# STM32H7RSxx register map
File version: 0.1
CPU: CM7 r0p1, little endian, MPU, FPU, 4 interrupt priority bits
Registers are 32-bit, read-write, reset 0x0 unless marked. A register's access mark holds for its fields unless they carry their own. Offsets are from the block's base; [hi:lo] are bit positions; lines under a group give offsets from that group; {n}, {i} and the like mark numbered series; <NAME> marks a mode.

## I3C1 (part 1 of 2) — Improved inter-integrated circuit
Base 0x40005400
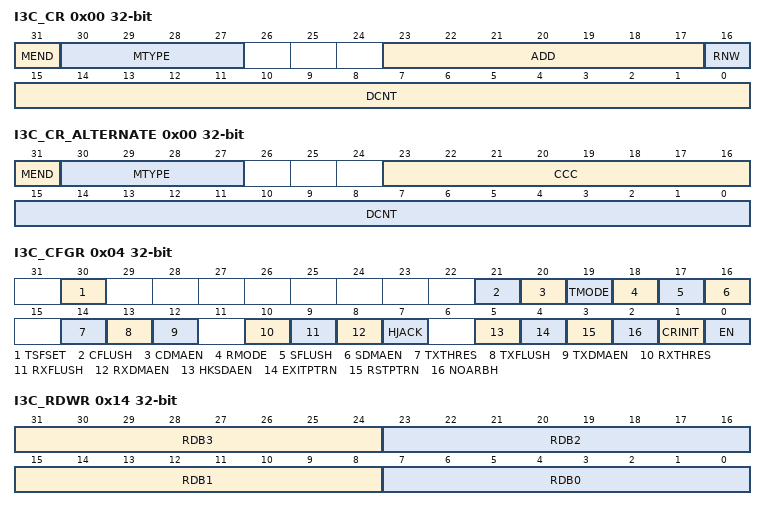
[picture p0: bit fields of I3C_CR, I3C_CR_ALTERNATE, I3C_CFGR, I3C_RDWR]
0x00 I3C_CR wo — I3C message control register
  [31] MEND — message end type (when the I3C is acting as controller)
    0=this message from controller ends with a Repeated START (Sr); 1=this message from controller ends with a STOP (P), being the last message of a frame
  [30:27] MTYPE — message type (whatever I3C is acting as controller/target) Bits[26:0] are ignored. After M2 error detection on an I3C SDR message, this is needed for SCL â€œstuck atâ€ recovery. Bits[26:0] are ignored. If I3C_CFGR.EXITPTRN=1, an HDR exit pattern is emitted on the bus to generate an escalation fault. Bits[23:17] (ADD[6:0]) is the emitted 7-bit dynamic address. Bit[16] (RNW) is the emitted RnW bit. The transferred private message is: {S / S+7â€™h7E+RnW=0+Sr / Sr+*} + 7-bit DynAddr + RnW + (8-bit Data + T)* + Sr/P. After a S (START), depending on I3C_CFGR.NOARBH, the arbitrable header (7â€™h7E+RnW=0) is inserted or not. Sr+*: after a Sr (Repeated Start), the hardware automatically inserts (7â€™h7E+RnW=0) if needed, i.e. if it follows an I3C direct message without ending by a P (Stop). Bits[23:17] (ADD[6:0]) is the emitted 7-bit dynamic address. Bit[16] (RNW) is the emitted RnW bit. The transferred direct message is: Sr + 7-bit DynAddr + RnW + (8-bit Data + T)* + Sr/P Bits[23:17] (ADD[6:0]) is the emitted 7-bit static address. Bit[16] (RNW) is the emitted RnW bit. The transferred legacy I2C message is: {S / S+ 7â€™h7E+RnW=0 + Sr / Sr+*} + 7-bit StaAddr + RnW + (8-bit Data + T)* + Sr/P. After a S (START), depending on I3C_CFGR.NOARBH, the arbitrable header (7â€™h7E+RnW=0) is inserted or not. Sr+*: after a Sr (Repeated Start), the hardware automatically inserts (7â€™h7E+RnW=0) if needed, i.e. if it follows an I3C direct message without ending by a P (Stop). 1xxx: reserved (when I3C is acting as I3C controller, used when target) 0xxx: reserved {S +} 7â€™h02 addr + RnW=0 {S +} 7-bit I3C_DEVR0.DA[6:0] + RnW=0 after a bus available condition (the target first emits a START request), or once the controller drives a START. {S +} 7-bit I3C_DEVR0.DA[6:0] + RnW=1 (+Ack/Nack from controller) When acknowledged from controller, the next (optional, depending on I3C_BCR.BCR2) transmitted IBI payload data is defined by I3C_CR.DCNT[15:0] and must be consistently programmed vs the maximum IBI payload data size which is defined by I3C_IBIDR.IBIP[2:0]. Others: reserved
    0=B_0x0_WHEN_I3C_IS_ACTING_AS_I3C_CONTROLLER (SCL output clock stops running until next control word is executed); 1=B_0x1_WHEN_I3C_IS_ACTING_AS_I3C_CONTROLLER (header message); 2=B_0x2_WHEN_I3C_IS_ACTING_AS_I3C_CONTROLLER (private message); 3=B_0x3_WHEN_I3C_IS_ACTING_AS_I3C_CONTROLLER (direct message (2nd part of an I3C SDR direct CCC command)); 4=B_0x4_WHEN_I3C_IS_ACTING_AS_I3C_CONTROLLER (legacy I2C message); 6=B_0x6_WHEN_I3C_IS_ACTING_AS_I3C_CONTROLLER (reserved (for this 1st alternate register description)); 8=B_0x8_WHEN_I3C_IS_ACTING_AS_I3C_TARGET (hot-join request (W)); 9=B_0x9_WHEN_I3C_IS_ACTING_AS_I3C_TARGET (controller-role request (W)); 10=B_0xA_WHEN_I3C_IS_ACTING_AS_I3C_TARGET (IBI (in-band interrupt) request (R))
  [23:17] ADD — 7-bit I3C dynamic / I2C static target address (when I3C is acting as controller) When I3C is acting as controller, this field is used if MTYPE[3:0]=0010 (private message) or MTYPE[3:0]=0011 (direct message) or MTYPE[3:0]=0100 (legacy I2C message)
  [16] RNW — read / non-write message (when I3C is acting as controller) When I3C is acting as controller, this field is used if MTYPE[3:0]=0010 (private message) or MTYPE[3:0]=0011 (direct message) or MTYPE[3:0]=0100 (legacy I2C message), in order to emit the RnW bit on the I3C bus.
    0=write message; 1=read message
  [15:0] DCNT — count of data to transfer during a read or write message, in bytes (whatever I3C is acting as controller/target) Linear encoding up to 64 Kbytes -1 ...
    0=no data to transfer; 1=1 byte; 2=2 bytes; 0xFFFF=64 Kbytes - 1 byte
0x00 I3C_CR_ALTERNATE wo (alternate view of I3C_CR) — I3C message control register alternate
  [31] MEND — message end type (when I3C is acting as controller)
    0=this message from the controller ends with a Repeated START (Sr); 1=the message from the controller ends with a STOP (P), being the last message of a frame
  [30:27] MTYPE — message type (when I3C is acting as controller) Bits[23:16] (CCC[7:0]) is the emitted 8-bit CCC code If Bit[23]=CCC[7]=1: this is the 1st part of an I3C SDR direct CCC command The transferred direct CCC command message is: {S / S+7â€™h7E +RnW=0 / Sr+*} + (direct CCC + T) + (8-bit Data + T)* + Sr After a S (START), depending on I3C_CFGR.NOARBH, the arbitrable header (7â€™h7E+RnW=0) is inserted or not. Sr+*: after a Sr (Repeated Start), the hardware automatically inserts (7â€™h7E+R/W). If Bit[23]=CCC[7]=0: this is an I3C SDR broadcast CCC command (including ENTDAA and ENTHDR0) The transferred broadcast CCC command message is: {S / S+7â€™h7E +RnW=0 / Sr+*} + (broadcast CCC + T) + (8-bit Data + T)* + Sr/P After a S (START), depending on I3C_CFGR.NOARBH, the arbitrable header (7â€™h7E+RnW=0) is inserted or not. Sr+*: after a Sr (Repeated Start), the hardware automatically inserts (7â€™h7E+R/W). others: reserved
    6=B_0x6_WHEN_I3C_IS_ACTING_AS_I3C_CONTROLLER (CCC command)
  [23:16] CCC — 8-bit CCC code (when I3C is acting as controller) If Bit[23]=CCC[7]=1, this is the 1st part of an I3C SDR direct CCC command. If Bit[23]=CCC[7]=0, this is an I3C SDR broadcast CCC command (including ENTDAA and ENTHDR0).
  [15:0] DCNT — count of data to transfer during a read or write message, in bytes (when I3C is acting as controller) Linear encoding up to 64 Kbytes -1. ...
    0=no data to transfer (allowed for write message and only for GET CCC read commands. Mandated value when emitting ENTDAA); 1=1 byte; 2=2 bytes; 0xFFFF=64 Kbytes - 1 byte
0x04 I3C_CFGR access per field — I3C configuration register
  [30] TSFSET wo — frame transfer set (a.k.a. software trigger) (when I3C is acting as controller) This bit can only be written. When I3C is acting as I3C controller: Note: If this bit is not set, the other alternative for the software to initiate a frame transfer is to directly write the first control word register (i.e. I3C_CR) while C-FIFO is empty (i.e. I3C_EVR.CFEF=1). Then, if the first written control word is not tagged as a message end (i.e I3C_CR.MEND=0), it causes the hardware to assert the flag I3C_EVR.CFNFF (C-FIFO not full and a next control word is needed).
    0=no action; 1=setting this bit initiates a frame transfer by causing the hardware to assert the flag I3C_EVR.CFNFF (C-FIFO not full and a control word is needed)
  [21] CFLUSH wo — C-FIFO flush (when I3C is acting as controller) This bit can only be written.
    0=no action; 1=flush C-FIFO
  [20] CDMAEN rw — C-FIFO DMA request enable (when I3C is acting as controller) When I3C is acting as controller: - Software writes and pushes control word(s) into C-FIFO i.e. writes I3C_CR register, as needed for a given frame. - A next control word transfer can be written by software either via polling on the flag I3C_EVR.CFNFF=1 or via interrupt notification (enabled by I3C_IER.CFNFIE=1). - DMA writes and pushes control word(s) into C-FIFO i.e. writes I3C_CR register, as needed for a given frame. - A next control word transfer is automatically written by the programmed hardware (i.e. via the asserted C-FIFO DMA request from the I3C and the programmed DMA channel).
    0=DMA mode is disabled for C-FIFO; 1=DMA mode is enabled for C-FIFO
  [19] TMODE rw — transmit mode (when I3C is acting as controller) When I3C is acting as I3C controller, this bit is used for the C-FIFO and TX-FIFO management vs the emitted frame on the I3C bus. A frame transfer starts as soon as first control word is present in C-FIFO.
    0=C-FIFO and TX-FIFO are not preloaded before starting to emit a frame transfer; 1=C-FIFO and TX-FIFO are first preloaded (also TX-FIFO if needed (depending on the frame format) before starting to emit a frame transfer
  [18] RMODE rw — S-FIFO enable / status receive mode (when I3C is acting as controller) When I3C is acting as I3C controller, this bit is used for the enabling the FIFO for the status (S-FIFO) vs the received status from the target on the I3C bus. When I3C is acting as target, this bit must be cleared. - Status register (i.e. I3C_SR) is used without FIFO mechanism. - There is no SCL stretch if a new status register content is not read. - Status register must be read before being lost/overwritten. All message status must be read. There is SCL stretch when there is no more space in the S-FIFO.
    0=S-FIFO is disabled, and the; 1=S-FIFO is enabled
  [17] SFLUSH wo — S-FIFO flush (when I3C is acting as controller) When I3C is acting as I3C controller, this bit can only be written (and is only used when I3C is acting as controller).
    0=no action; 1=flush S-FIFO
  [16] SDMAEN rw — S-FIFO DMA request enable (when I3C is acting as controller) Condition: When RMODE=1 (FIFO is enabled for the status): - Software reads and pops a status word from S-FIFO i.e. reads I3C_SR register after a completed frame (I3C_EVR.FCF=1) or an error (I3C_EVR.ERRF=1). - A status word can be read by the software either via polling on these register flags or via interrupt notification (enabled by I3C_IER.FCIE=1 and I3C_IER.ERRIE=1). - DMA reads and pops status word(s) from S-FIFO i.e. reads I3C_SR register. - Status word(s) are automatically read by the programmed hardware (i.e. via the asserted S-FIFO DMA request from the I3C and the programmed DMA channel).
    0=DMA mode is disabled for S-FIFO; 1=DMA mode is enabled for S-FIFO
  [14] TXTHRES rw — TX-FIFO threshold (whatever I3C is acting as controller/target) This threshold defines, compared to the TX-FIFO level, when the I3C_EVR.TXFNFF flag is set (and consequently if TXDMAEN=1 when is asserted a DMA TX request). TXFNFF is set when 1 byte is to be written in TX-FIFO (i.e. in I3C_TDR). TXFNFF is set when 4 bytes are to be written in TX-FIFO (i.e. in I3C_TDWR).
    0=1-byte threshold; 1=4-byte threshold
  [13] TXFLUSH wo — TX-FIFO flush (whatever I3C is acting as controller/target) This bit can only be written. When the I3C is acting as target, this bit can be used to flush the TX-FIFO on a private read if the controller has early ended the read data (i.e. driven low the T bit) and there is/are remaining data in the TX-FIFO (i.e. I3C_SR.ABT=1 and I3C_SR.XDCNT[15:0] < I3C_TGTTDR.TGTTDCNT[15:0]).
    0=no action; 1=flush TX-FIFO
  [12] TXDMAEN rw — TX-FIFO DMA request enable (whatever I3C is acting as controller/target) - Software writes and pushes a data byte/word into TX-FIFO i.e. writes I3C_TDR or I3C_TDWR register, to be transmitted over the I3C bus. - A next data byte/word is to be written by the software either via polling on the flag I3C_EVR.TXFNFF=1 or via interrupt notification (enabled by I3C_IER.TXFNFIE=1). - DMA writes and pushes data byte(s)/word(s) into TX-FIFO i.e. writes I3C_TDR or I3C_TDWR register. - A next data byte/word transfer is automatically pushed by the programmed hardware (i.e. via the asserted TX-FIFO DMA request from the I3C and the programmed DMA channel).
    0=DMA mode is disabled for TX-FIFO; 1=DMA mode is enabled for TX-FIFO
  [10] RXTHRES rw — RX-FIFO threshold (whatever I3C is acting as controller/target) This threshold defines, compared to the RX-FIFO level, when the I3C_EVR.RXFNEF flag is set (and consequently if RXDMAEN=1 when is asserted a DMA RX request). RXFNEF is set when 1 byte is to be read in RX-FIFO (i.e. in I3C_RDR). RXFNEF is set when 4 bytes are to be read in RX-FIFO (i.e. in I3C_RDWR).
    0=1-byte threshold; 1=4-byte threshold
  [9] RXFLUSH wo — RX-FIFO flush (whatever I3C is acting as controller/target) This bit can only be written.
    0=no action; 1=flush RX-FIFO
  [8] RXDMAEN rw — RX-FIFO DMA request enable (whatever I3C is acting as controller/target) - Software reads and pops a data byte/word from RX-FIFO i.e. reads I3C_RDR or I3C_RDWR register. - A next data byte/word is to be read by the software either via polling on the flag I3C_EVR.RXFNEF=1 or via interrupt notification (enabled by I3C_IER.RXFNEIE=1). - DMA reads and pops data byte(s)/word(s) from RX-FIFO i.e. reads I3C_RDR or I3C_RDWR register. - A next data byte/word is automatically read by the programmed hardware (i.e. via the asserted RX-FIFO DMA request from the I3C and the programmed DMA channel).
    0=DMA mode is disabled for RX-FIFO; 1=DMA mode is enabled for RX-FIFO
  [7] HJACK rw — Hot Join request acknowledge (when I3C is acting as a controller) After the NACK, the message continues as initially programmed (the hot-joining target is aware of the NACK and surely emits another hot-join request later on). After the ACK, the message continues as initially programmed. The software is aware by the HJ interrupt (flag I3C_EVR.HJF is set) and initiates the ENTDAA sequence later on, potentially preventing others Hot Join requests with a Disable target events command (DISEC, with DISHJ=1). Independently of the HJACK configuration, further Hot Join request(s) are NACKed until the Hot Join flag, HJF, is cleared. However, a NACKed target can be assigned a dynamic address by the ENTDAA sequence initiated later on by the first HJ request, preventing this target to emit an HJ request again.
    0=Hot Join request is NACKed; 1=Hot Join request is ACKed
  [5] HKSDAEN rw — High-keeper enable on SDA line (when I3C is acting as a controller) This bit can be modified only when I3C_CFGR.EN=0.
    0=High-Keeper is disabled; 1=High-Keeper is enabled, and the weak pull-up is effective on the T bit, instead of the open-drain class pull-up
  [4] EXITPTRN rw — HDR Exit Pattern enable (when I3C is acting as a controller) This bit can be modified only when there is no on-going frame. This is used to send only the header to test ownership of the bus when there is a suspicion of problem after controller-role hand-off (new controller didnâ€™t assert its controller-role by accessing the previous one in less than Activity State time). The HDR Exit Pattern is sent even if the message header {S/Sr + 0x7E addr + W } is ACKed.
    0=HDR Exit Pattern is not sent after the message header (MTYPE[3:0]=0001); 1=HDR Exit Pattern is sent after the message header (MTYPE[3:0]=0001) to generate an escalation fault
  [3] RSTPTRN rw — HDR reset pattern enable (when I3C is acting as a controller) This bit can be modified only when there is no on-going frame.
    0=standard STOP emitted at the end of a frame; 1=HDR reset pattern is inserted before the STOP of any emitted frame that includes a RSTACT CCC command
  [2] NOARBH rw — no arbitrable header after a START (when I3C is acting as a controller) This bit can be modified only when there is no on-going frame. - The target address is emitted directly after a START in case of a legacy I2C message or an I3C SDR private read/write message. - This is a more performing option (when is useless the emission of the 0x7E arbitrable header), but this is to be used only when the controller is sure that the addressed target device can not emit concurrently an IBI or a controller-role request (to insure no misinterpretation and no potential conflict between the address emitted by the controller in open-drain mode and the same address a target device can emit after a START, for IBI or MR).
    0=An arbitrable header (7â€™h7E + RnW=0) is emitted after a START and before a legacy I2C message or an I3C SDR private read/write message (default); 1=No arbitrable header
  [1] CRINIT rw — initial controller/target role This bit can be modified only when I3C_CFGR.EN = 0. Once enabled by setting I3C_CFGR.EN = 1, I3C peripheral initially acts as an I3C target. I3C does not drive SCL line and does not enable SDA pull-up, until it eventually acquires the controller role. Once enabled by setting I3C_CFGR.EN = 1, I3C peripheral initially acts as a controller. It has the I3C controller role, so drives SCL line and enables SDA pull-up, until it eventually offers the controller role to an I3C secondary controller.
    0=target role; 1=controller role
  [0] EN rw — I3C enable (whatever I3C is acting as controller/target) - Except registers, the peripheral is under reset (a.k.a. partial reset). - Before clearing EN, when I3C is acting as a controller, all the possible target requests must be disabled using DISEC CCC. - When I3C is acting as a target, software should not disable the I3C, unless a partial reset is needed. In this state, some register fields can not be modified (like CRINIT, HKSDAEN for the I3C_CFGR)
    0=I3C is disabled; 1=I3C is enabled
0x10 I3C_RDR ro — I3C receive data byte register
  [7:0] RDB0 — 8-bit received data on I3C bus.
0x14 I3C_RDWR ro — I3C receive data word register
  [31:24] RDB3 — 8-bit received data (latest byte on I3C bus).
  [23:16] RDB2 — 8-bit received data (next byte after RDB1 on I3C bus).
  [15:8] RDB1 — 8-bit received data (next byte after RDB0 on I3C bus).
  [7:0] RDB0 — 8-bit received data (earliest byte on I3C bus).
0x18 I3C_TDR wo — I3C transmit data byte register
  [7:0] TDB0 — 8-bit data to transmit on I3C bus.
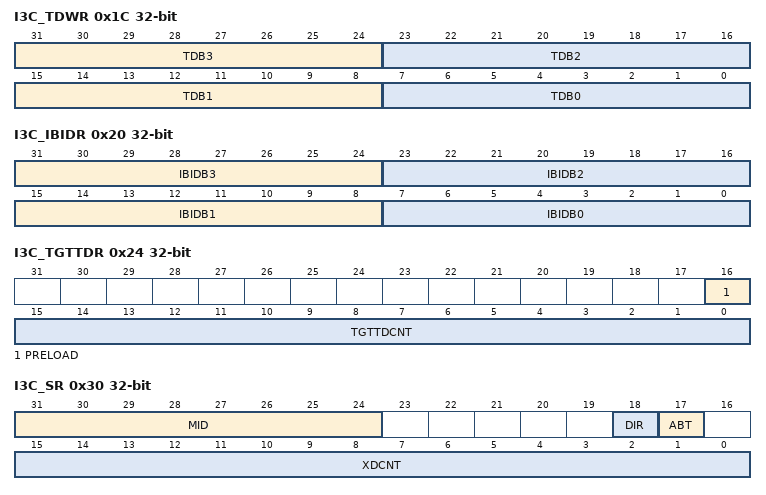
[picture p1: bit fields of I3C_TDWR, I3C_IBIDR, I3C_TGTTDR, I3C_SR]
0x1C I3C_TDWR wo — I3C transmit data word register
  [31:24] TDB3 — 8-bit transmit data (latest byte on I3C bus).
  [23:16] TDB2 — 8-bit transmit data (next byte after TDB1[7:0] on I3C bus).
  [15:8] TDB1 — 8-bit transmit data (next byte after TDB0[7:0] on I3C bus).
  [7:0] TDB0 — 8-bit transmit data (earliest byte on I3C bus)
0x20 I3C_IBIDR — I3C IBI payload data register
  [31:24] IBIDB3 — 8-bit IBI payload data (latest byte on I3C bus).
  [23:16] IBIDB2 — 8-bit IBI payload data (next byte on I3C bus after IBIDB1[7:0]).
  [15:8] IBIDB1 — 8-bit IBI payload data (next byte on I3C bus after IBIDB0[7:0]).
  [7:0] IBIDB0 — 8-bit IBI payload data (earliest byte on I3C bus, i.e. MDB[7:0] mandatory data byte).
0x24 I3C_TGTTDR — I3C target transmit configuration register
  [16] PRELOAD — preload of the TX-FIFO (when I3C is configured as target) This bit must be written and asserted by software in the same access when is written and defined the number of bytes to preload into the TX-FIFO and to transmit. This bit is cleared by hardware when all the data bytes to transmit are loaded into the TX-FIFO.
    0=no TX-FIFO preload; 1=TX-FIFO preload
  [15:0] TGTTDCNT — transmit data counter, in bytes (when I3C is configured as target) This field must be written by software in the same access when is asserted PRELOAD, in order to define the number of bytes to preload and to transmit. This field is updated by hardware and reports, when read, the remaining number of bytes to be loaded into the TX-FIFO.
0x30 I3C_SR ro — I3C status register
  [31:24] MID — message identifier/counter of a given frame (when the I3C is acting as controller) When the I3C is acting as controller, this field identifies the control word message (i.e. I3C_CR) to which the I3C_SR status register refers. First message of a frame is identified with MID[7:0]=0. This field is incremented (by hardware) on the completion of a new message control word (i.e. I3C_CR) over I3C bus. This field is reset for every new frame start.
  [18] DIR — message direction Whatever the I3C is acting as controller or target, this bit indicates the direction of the related message on the I3C bus Note: ENTDAA CCC is considered as a write command.
    0=write; 1=read
  [17] ABT — a private read message is completed/aborted prematurely by the target (when the I3C is acting as controller) When the I3C is acting as controller, this bit indicates if the private read data which is transmitted by the target early terminates (i.e. the target drives T bit low earlier vs what does expect the controller in terms of programmed number of read data bytes i.e. I3C_CR.DCNT[15:0]).
    0=no early completion/abort from the target; 1=early completion/abort from the target
  [15:0] XDCNT — data counter - When the I3C is acting as controller: number of targets detected on the bus - When the I3C is acting as target: number of transmitted bytes - Whatever the I3C is acting as controller or target: number of data bytes read from or transmitted on the I3C bus during the MID[7:0] message
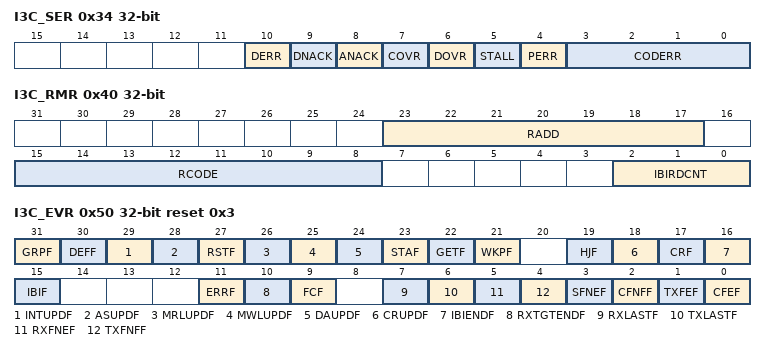
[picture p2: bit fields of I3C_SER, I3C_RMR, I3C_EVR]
0x34 I3C_SER ro — I3C status error register
  [10] DERR — data error (when the I3C is acting as controller)
    0=no detected error; 1=controller detected a data error during the controller-role hand-off procedure (GETACCCR CCC, formerly known as GETACCMST) when the received target address or/and the parity bit do no match. Active controller keeps controller-role.
  [9] DNACK — data not acknowledged (when the I3C is acting as controller) i) a legacy I2C write transfer ii) the second trial when sending dynamic address during ENTDAA procedure
    0=no detected error; 1=controller detected that a data byte is not acknowledged by a target, either during:
  [8] ANACK — address not acknowledged (when the I3C is configured as controller) i) a legacy I2C read/write transfer ii) a direct CCC write transfer iii) the second trial of a direct CCC read transfer iv) a private read/write transfer
    0=no detected error; 1=controller detected that the static/dynamic address was not acknowledged by a target, either during:
  [7] COVR — C-FIFO underrun or S-FIFO overrun (when the I3C is acting as controller) i) a C-FIFO underrun: control FIFO is empty and a restart has to be emitted ii) a S-FIFO overrun: S-FIFO is full and a new message ends
    0=no detected error; 1=controller detected either:
  [6] DOVR — RX-FIFO overrun or TX-FIFO underrun i) a TX-FIFO underrun: TX-FIFO is empty and a write data byte has to be transmitted ii) a RX-FIFO overrun: RX-FIFO is full and a new data byte is received
    0=no detected error; 1=whatever controller or target, hardware detected either:
  [5] STALL — SCL stall error (when the I3C is acting as target)
    0=no detected error; 1=target detected that SCL was stable for more than 125 ï¿½s during a I3C SDR read
  [4] PERR — protocol error
    0=no detected error; 1=whatever controller or target, hardware detected a protocol error, as detailed in CODERR[3:0]
  [3:0] CODERR — protocol error code/type controller detected an illegally formatted CCC controller detected that transmitted data on the bus is different from expected controller detected a not acknowledged broadcast address (7â€™hE) controller detected the new controller did not drive bus after controller-role hand-off target detected an invalid broadcast address 7â€™hE+W target detected a parity error on a CCC code via a parity check (vs T bit) target detected a parity error on a write data via a parity check (vs T bit) target detected a parity error on the assigned address during dynamic address arbitration via a parity check (vs PAR bit) target detected a 7â€™hE+R missing after Sr during dynamic address arbitration target detected an illegally formatted CCC target detected that transmitted data on the bus is different from expected others: reserved
    0=CE0 error (transaction after sending CCC):; 1=CE1 error (monitoring error):; 2=CE2 error (no response to broadcast address):; 3=CE3 error (failed controller-role hand-off):; 8=TE0 error (invalid broadcast address 7â€™hE+W):; 9=TE1 error (CCC code):; 10=TE2 error (write data):; 11=TE3 error (assigned address during dynamic address arbitration):; 12=TE4 error (7â€™hE+R missing after Sr during dynamic address arbitration):; 13=TE5 error (transaction after detecting CCC):; 14=TE6 error (monitoring error):
0x40 I3C_RMR ro — I3C received message register
  [23:17] RADD — received target address (when the I3C is configured as controller) When the I3C is configured as controller, this field logs the received dynamic address from the target during acknowledged IBI or controller-role request.
  [15:8] RCODE — received CCC code (when the I3C is configured as target) When the I3C is configured as target, this field logs the received CCC code.
  [2:0] IBIRDCNT — IBI received payload data count (when the I3C is configured as controller) When the I3C is configured as controller, this field logs the number of data bytes effectively received in the I3C_IBIDR register.
0x50 I3C_EVR ro reset 0x3 — I3C event register
  [31] GRPF — group addressing flag (when the I3C is acting as target) When the I3C is acting as target (and is typically controller capable), this flag is asserted by hardware to indicate that the broadcast DEFGRPA CCC (define list of group addresses) has been received. Then, software may store the received data for when getting the controller role. This flag is cleared when software writes 1 into corresponding I3C_CEVR.CGRPF bit.
  [30] DEFF — DEFTGTS flag (when the I3C is acting as target) When the I3C is acting as target (and is typically controller capable), this flag is asserted by hardware to indicate that the broadcast DEFTGTS CCC (define list of targets) has been received. Then, software may store the received data for when getting the controller role. This flag is cleared when software writes 1 into corresponding I3C_CEVR.CDEFF bit.
  [29] INTUPDF — interrupt/controller-role/hot-join update flag (when the I3C is acting as target) When the I3C is acting as target, this flag is asserted by hardware to indicate that the direct or broadcast ENEC/DISEC CCC (enable/disable target events) has been received, where a target event is either an interrupt/IBI request, a controller-role request, or an hot-join request. Then, software should read respectively I3C_DEVR0.IBIEN, I3C_DEVR0.CREN or I3C_DEVR0.HJEN. This flag is cleared when software writes 1 into corresponding I3C_CEVR.CINTUPDF bit.
  [28] ASUPDF — activity state update flag (when the I3C is acting as target) When the I3C is acting as target, this flag is asserted by hardware to indicate that the direct or broadcast ENTASx CCC (with x=0...3) has been received. Then, software should read I3C_DEVR0.AS[1:0]. This flag is cleared when software writes 1 into corresponding I3C_CEVR.CASUPDF bit.
  [27] RSTF — reset pattern flag (when the I3C is acting as target) When the I3C is acting as target, this flag is asserted by hardware to indicate that a reset pattern has been detected (i.e. 14 SDA transitions while SCL is low, followed by repeated start, then stop). Then, software should read I3C_DEVR0.RSTACT[1:0] and I3C_DEVR0.RSTVAL, to know what reset level is required. If RSTVAL=1: when the RSTF is asserted (and/or the corresponding interrupt if enabled), I3C_DEVR0.RSTACT[1:0] dictates the reset action to be performed by the software if any. If RSTVAL=0: when the RSTF is asserted (and/or the corresponding interrupt if enabled), the software should issue an I3C reset after a first detected reset pattern, and a system reset on the second one. The corresponding interrupt may be used to wakeup the device from a low power mode (Sleep or Stop mode). This flag is cleared when software writes 1 into corresponding I3C_CEVR.CRSTF bit.
  [26] MRLUPDF — maximum read length update flag (when the I3C is acting as target) When the I3C is acting as target, this flag is asserted by hardware to indicate that a direct SETMRL CCC (set max read length) has been received. Then, software should read I3C_MAXRLR.MRL[15:0] to get the maximum read length value. This flag is cleared when software writes 1 into corresponding I3C_CEVR.CMRLUPDF bit.
  [25] MWLUPDF — maximum write length update flag (when the I3C is acting as target) When the I3C is acting as target, this flag is asserted by hardware to indicate that a direct SETMWL CCC (set max write length) has been received. Then, software should read I3C_MAXWLR.MWL[15:0] to get the maximum write length value. This flag is cleared when software writes 1 into corresponding I3C_CEVR.CMWLUPDF bit.
  [24] DAUPDF — dynamic address update flag (when the I3C is acting as target) When the I3C is acting as target, this flag is asserted by hardware to indicate that a dynamic address update has been received via any of the broadcast ENTDAA, RSTDAA and direct SETNEWDA CCC. Then, software should read I3C_DEVR0.DA[6:0] to get the maximum write length value. This flag is cleared when software writes 1 into corresponding I3C_CEVR.CDAUPDF bit.
  [23] STAF — get status flag (when the I3C is acting as target) When the I3C is acting as target, this flag is asserted by hardware to indicate that a direct GETSTATUS CCC (get status) has been received. This flag is cleared when software writes 1 into corresponding I3C_CEVR.CSTAF bit.
  [22] GETF — get flag (when the I3C is acting as target) When the I3C is acting as target, this flag is asserted by hardware to indicate that any direct CCC of get type (GET*** CCC) has been received. This flag is cleared when software writes 1 into corresponding I3C_CEVR.CGETF bit.
  [21] WKPF — wakeup/missed start flag (when the I3C is acting as target) When the I3C is acting as target, this flag is asserted by hardware to indicate that a start has been detected (i.e. a SDA falling edge followed by a SCL falling edge) but on the next SCL falling edge, the I3C kernel clock is (still) gated. Thus an I3C bus transaction may have been lost by the target. The corresponding interrupt may be used to wakeup the device from a low power mode (Sleep or Stop mode). This flag is cleared when software writes 1 into corresponding I3C_CEVR.CWKPF bit.
  [19] HJF — hot-join flag (when the I3C is acting as controller) When the I3C is acting as controller, this flag is asserted by hardware to indicate that an hot join request has been received. This flag is cleared when software writes 1 into corresponding I3C_CEVR.CHJF bit.
  [18] CRUPDF — controller-role update flag (when the I3C is acting as target) When the I3C is acting as target, this flag is asserted by hardware to indicate that it has now gained the controller role after the completed controller-role hand-off procedure. This flag is cleared when software writes 1 into corresponding I3C_CEVR.CCRUPDF bit.
  [17] CRF — controller-role request flag (when the I3C is acting as controller) When the I3C is acting as controller, this flag is asserted by hardware to indicate that a controller-role request has been acknowledged and completed (by hardware). The software should then issue a GETACCCR CCC (get accept controller role) for the controller-role hand-off procedure. This flag is cleared when software writes 1 into corresponding I3C_CEVR.CCRF bit.
  [16] IBIENDF — IBI end flag (when the I3C is acting as target) When the I3C is acting as target, this flag is asserted by hardware to indicate that a IBI transfer has been received and completed (IBI acknowledged and IBI data bytes read by controller if any). This flag is cleared when software writes 1 into corresponding I3C_CEVR.CIBIENDF bit.
  [15] IBIF — IBI flag (when the I3C is acting as controller) When the I3C is acting as controller, this flag is asserted by hardware to indicate that an IBI request has been received. This flag is cleared when software writes 1 into corresponding I3C_CEVR.CIBIF bit.
  [11] ERRF — flag (whatever the I3C is acting as controller/target) This flag is asserted by hardware to indicate that an error occurred.Then, software should read I3C_SER to get the error type. This flag is cleared when software writes 1 into corresponding I3C_CEVR.CERRF bit.
  [10] RXTGTENDF — target-initiated read end flag (when the I3C is acting as controller) When the I3C is acting as controller, this flag is asserted by hardware to indicate that the target has prematurely ended a read transfer. Then, software should read I3C_SR to get more information on the prematurely read transfer. This flag is cleared when software writes 1 into corresponding I3C_CEVR.CRXTGTENDF bit.
  [9] FCF — frame complete flag (whatever the I3C is acting as controller/target) When the I3C is acting as controller, this flag is asserted by hardware to indicate that a frame has been (normally) completed on the I3C bus, i.e when a stop is issued. When the I3C is acting as target, this flag is asserted by hardware to indicate that a message addressed to/by this target has been (normally) completed on the I3C bus, i.e when a next stop or repeated start is then issued by the controller. This flag is cleared when software writes 1 into corresponding I3C_CEVR.CFCF bit.
  [7] RXLASTF — last read data byte/word flag (whatever the I3C is acting as controller/target) This flag is asserted by hardware to indicate that the last data byte/word (depending on I3C_CFGR.RXTHRES) of a message is to be read from the RX-FIFO. This flag is de-asserted by hardware when the last data byte/word of a message is read.
  [6] TXLASTF — last written data byte/word flag (whatever the I3C is acting as controller/target) This flag is asserted by hardware to indicate that the last data byte/word (depending on I3C_CFGR.TXTHRES) of a message is to be written to the TX-FIFO. This flag is de-asserted by hardware when the last data byte/word of a message is written.
  [5] RXFNEF — RX-FIFO not empty flag (whatever the I3C is acting as controller/target) This flag is asserted by hardware to indicate that a data byte is to be read from the RX-FIFO. This flag is de-asserted by hardware to indicate that a data byte is not to be read from the RX-FIFO. Note: The software must wait for RXFNEF=1 (by polling or via the enabled interrupt) before reading from RX-FIFO (i.e. writing to I3C_RDR or I3C_RDWR depending on I3C_CFGR.RXTHRES).
  [4] TXFNFF — TX-FIFO not full flag (whatever the I3C is acting as controller/target) This flag is asserted by hardware to indicate that a data byte/word is to be written to the TX-FIFO. This flag is de-asserted by hardware to indicate that a data byte/word is not to be written to the TX-FIFO. Note: The software must wait for TXFNFF=1 (by polling or via the enabled interrupt) before writing to TX-FIFO (i.e. writing to I3C_TDR or I3C_TDWR depending on I3C_CFGR.TXTHRES). Note: When the I3C is acting as target, if the software intends to use the TXFNFF flag for writing into I3C_TDR/I3C_TDWR, it must have configured and set the TX-FIFO preload (i.e. write I3C_TGTTDR.PRELOAD).
  [3] SFNEF — S-FIFO not empty flag (when the I3C is acting as controller) When the I3C is acting as controller, if the S-FIFO is enabled (i.e. I3C_CFGR.RMODE=1), this flag is asserted by hardware to indicate that a status word is to be read from the S-FIFO. This flag is de-asserted by hardware to indicate that a status word is not to be read from the S-FIFO.
  [2] CFNFF — C-FIFO not full flag (when the I3C is acting as controller) When the I3C is acting as controller, this flag is asserted by hardware to indicate that a control word is to be written to the C-FIFO. This flag is de-asserted by hardware to indicate that a control word is not to be written to the C-FIFO. Note: The software must wait for CFNFF=1 (by polling or via the enabled interrupt) before writing to C-FIFO (i.e. writing to I3C_CR).
  [1] TXFEF — TX-FIFO empty flag (whatever the I3C is acting as controller/target) This flag is asserted by hardware to indicate that the TX-FIFO is empty. This flag is de-asserted by hardware to indicate that the TX-FIFO is not empty. Note: When the I3C is acting as controller, if the C-FIFO and TX-FIFO preload is configured (i.e. I3C_CFGR.TMODE=1), the software must wait for TXFEF=1 and CFEF=1 before starting a new frame transfer.
  [0] CFEF — C-FIFO empty flag (whatever the I3C is acting as controller/target) This flag is asserted by hardware to indicate that the C-FIFO is empty when controller, and that the I3C_CR register contains no control word (i.e. none IBI/CR/HJ request) when target. This flag is de-asserted by hardware to indicate that the C-FIFO is not empty when controller, and that the I3C_CR register contains one control word (i.e. a pending IBI/CR/HJ request) when target. Note: When the I3C is acting as controller, if the C-FIFO and TX-FIFO preload is configured (i.e. I3C_CFGR.TMODE=1), the software must wait for TXFEF=1 and CFEF=1 before starting a new frame transfer.
